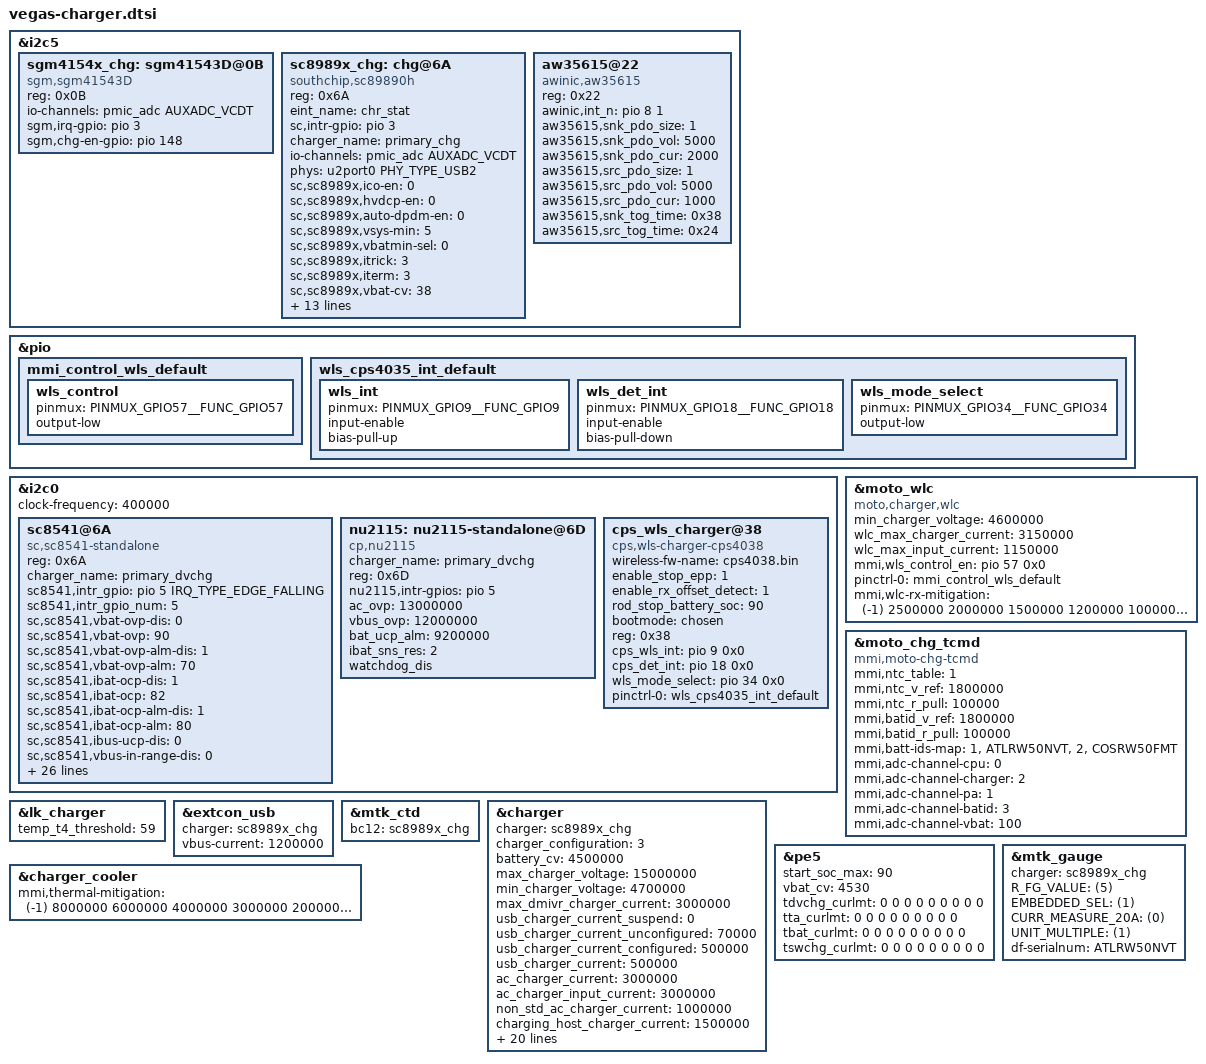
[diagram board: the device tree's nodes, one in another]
/*
 * Copyright (c) 2019 MediaTek Inc.
 *
 * This program is free software; you can redistribute it and/or modify
 * it under the terms of the GNU General Public License version 2 as
 * published by the Free Software Foundation.
 *
 * This program is distributed in the hope that it will be useful,
 * but WITHOUT ANY WARRANTY; without even the implied warranty of
 * MERCHANTABILITY or FITNESS FOR A PARTICULAR PURPOSE.  See the
 * GNU General Public License for more details.
 */
#include <dt-bindings/iio/mt635x-auxadc.h>
&i2c5 {
	sgm4154x_chg: sgm41543D@0B {
		status = "okay";
		compatible = "sgm,sgm41543D";
		reg = <0x0B>;
                io-channels = <&pmic_adc AUXADC_VCDT>;
		io-channel-names = "pmic_vbus";
		sgm,irq-gpio = <&pio 3 IRQ_TYPE_EDGE_FALLING>;     //irq num base on hardware design
		sgm,chg-en-gpio = <&pio 148 0>;   //gpio num base on hardware design  1.MTK parent node name is pio  2.QUALCOMM parent node name is tlmm or other
	};
	sc8989x_chg: chg@6A {
		compatible = "southchip,sc89890h";
		reg = <0x6A>;
		status = "okay";
		eint_name = "chr_stat";
		sc,intr-gpio = <&pio 3 IRQ_TYPE_EDGE_FALLING>;
		charger_name = "primary_chg";
		io-channels = <&pmic_adc AUXADC_VCDT>;
		io-channel-names = "pmic_vbus";
		phys = <&u2port0 PHY_TYPE_USB2>;
		phy-names = "usb2-phy";
		sc,sc8989x,ico-en = <0>;
		sc,sc8989x,hvdcp-en = <0>;
		sc,sc8989x,auto-dpdm-en = <0>;
		sc,sc8989x,vsys-min = <5>; /*3500mV*/
		sc,sc8989x,vbatmin-sel = <0>; /*0:2.9V 1:2.5V*/
		sc,sc8989x,itrick = <3>; /*60 + val *60*/
		sc,sc8989x,iterm = <3>; /*30 + val * 60*/
		sc,sc8989x,vbat-cv = <38>; /*3840 + val * 16*/
		sc,sc8989x,vbat-low = <1>; /*0:2.8V 1:3V*/
		sc,sc8989x,vrechg = <0>; /*0:100mV 1:200mV*/
		sc,sc8989x,en-term = <1>;
		sc,sc8989x,stat-dis = <0>;
		sc,sc8989x,wd-time = <0>; /*0:Dis 1:40s 2:80s 3:160s*/
		sc,sc8989x,en-timer = <1>;
		sc,sc8989x,charge-timer = <2>; /*0:5h 1:8h 2:12h 3:20h*/
		sc,sc8989x,bat-comp = <0>; /*val * 20*/
		sc,sc8989x,vclamp = <0>; /*val *32*/
		sc,sc8989x,votg = <12>; /*3900 + val * 100*/
		sc,sc8989x,iboost = <7>; /*0:0.5A 3:1.4A 5:1.875A 7:2.45A*/
		sc,sc8989x,force_vindpm = <0>;
		sc,sc8989x,vindpm = <18>; /*2600 + val * 100*/
	};
        aw35615@22 {
                compatible = "awinic,aw35615";
                reg = <0x22>;
                status = "okay";
                awinic,int_n = <&pio 8 1>;
                aw35615,snk_pdo_size = <1>; /* set sink pdo num*/
                aw35615,snk_pdo_vol = <5000>; /* set sink pdo voltage mV*/
                aw35615,snk_pdo_cur = <2000>; /* set sink pdo current mA*/
                aw35615,src_pdo_size = <1>; /* set source pdo num*/
                aw35615,src_pdo_vol = <5000>; /* set source pdo voltage mV*/
                aw35615,src_pdo_cur = <1000>; /* set source pdo current mA*/
                aw35615,snk_tog_time = <0x38>; /* set toggle sink time */
                aw35615,src_tog_time = <0x24>; /* set toggle source time */
        };
};

&pio {
       mmi_control_wls_default: mmi_control_wls_default {
               wls_control {
                       pinmux = <PINMUX_GPIO57__FUNC_GPIO57>;
                      output-low;
               };
       };

       wls_cps4035_int_default: wls_cps4035_int_default {
               wls_int {
                       pinmux = <PINMUX_GPIO9__FUNC_GPIO9>;
                       input-enable;
                       bias-pull-up;
               };
               wls_det_int {
                       pinmux = <PINMUX_GPIO18__FUNC_GPIO18>;
                       input-enable;
                       bias-pull-down;
               };
               wls_mode_select {
                       pinmux = <PINMUX_GPIO34__FUNC_GPIO34>;
                       output-low;
                 };
       };
};

&i2c0 {
	clock-frequency = <400000>;
	sc8541@6A {
		compatible = "sc,sc8541-standalone";
		reg = <0x6A>;
		charger_name = "primary_dvchg";
		sc8541,intr_gpio = <&pio 5 IRQ_TYPE_EDGE_FALLING>;
		sc8541,intr_gpio_num = <5>;
		sc,sc8541,vbat-ovp-dis = <0>;
		sc,sc8541,vbat-ovp = <90>; /*3840 + val * 10*/
		sc,sc8541,vbat-ovp-alm-dis = <1>;
		sc,sc8541,vbat-ovp-alm = <70>; /*3840 + val * 10*/
		sc,sc8541,ibat-ocp-dis = <1>;
		sc,sc8541,ibat-ocp  = <82>; /*val * 100*/
		sc,sc8541,ibat-ocp-alm-dis = <1>;
		sc,sc8541,ibat-ocp-alm = <80>; /*val * 100*/
		sc,sc8541,ibus-ucp-dis = <0>;
		sc,sc8541,vbus-in-range-dis = <0>;
		sc,sc8541,vbus-pd-en = <0>;
		sc,sc8541,vbus-ovp = <80>; /*7000 + val * 50*/
		sc,sc8541,vbus-ovp-alm-dis = <1>;
		sc,sc8541,vbus-ovp-alm = <34>; /*7000 + val * 50*/
		sc,sc8541,ibus-ocp-dis = <0>;
		sc,sc8541,ibus-ocp = <13>; /*1000 + val * 250*/
		sc,sc8541,tshut-dis = <1>;
		sc,sc8541,tsbus-flt-dis = <1>;
		sc,sc8541,tsbat-flt-dis = <1>;
		sc,sc8541,tdie-alm = <200>; /*25 + val * 0.5*/
		sc,sc8541,tsbus-flt = <21>;
		sc,sc8541,tsbat-flt = <21>;
		sc,sc8541,vac1-ovp = <2>; /*0:6.5V 1:10.5V 2:12V 3:14V 4:16V 5~7:18V*/
		sc,sc8541,vac2-ovp = <3>; /*0:6.5V 1:10.5V 2:12V 3:14V 4:16V 5~7:18V*/
		sc,sc8541,vac1-pd-en = <0>;
		sc,sc8541,vac2-pd-en = <0>;
		sc,sc8541,fsw-set = <5>; /*0:200KHz 1:300KHz 2:400KHz
					3:500KHz 4:600KHz 5:650KHz 6:700KHz 7:750KHz*/
		sc,sc8541,wd-timeout = <0>; /*0:0.5s 1:1s 2:5s 3:30s*/
		sc,sc8541,wd-timeout-dis = <1>;
		sc,sc8541,ibat-sns-r = <0>; /*0:2mho 1:5mho*/
		sc,sc8541,ss-timeout = <7>; /*0:6.25ms 1:12.5ms 2:25ms 3:50ms
					4:100ms 5:400ms 6:1.5s 7:10s*/
		sc,sc8541,ibus-ucp-fall-dg = <1>;
		sc,sc8541,vout-ovp-dis = <0>;
		sc,sc8541,vout-ovp = <3>; /*4700 + val * 100*/
		sc,sc8541,pmid2out-uvp = <7>; /*50 + val * 25*/
		sc,sc8541,pmid2out-ovp = <7>; /*150 + val * 50*/
	};

	nu2115: nu2115-standalone@6D {
		compatible = "cp,nu2115";
		status = "okay";
		charger_name = "primary_dvchg";
		reg = <0x6D>;
		nu2115,intr-gpios = <&pio 5 0x0>;
		ac_ovp = <13000000>;
		vbus_ovp = <12000000>;
		bat_ucp_alm = <9200000>;
		ibat_sns_res = <2>;
		watchdog_dis;
	};

	cps_wls_charger@38 {
               compatible = "cps,wls-charger-cps4038";
               wireless-fw-name = "cps4038.bin";
               enable_stop_epp = <1>;
               enable_rx_offset_detect = <1>;
               /*stop rx offset detect battery soc*/
               rod_stop_battery_soc = <90>;
               bootmode = <&chosen>;
               reg = <0x38>;
               cps_wls_int = <&pio 9 0x0>;
               cps_det_int = <&pio 18 0x0>;
               wls_mode_select = <&pio 34 0x0>;
               pinctrl-names = "default";
               pinctrl-0 = <&wls_cps4035_int_default>;
               status = "okay";
       };

};

&moto_wlc {
       compatible = "moto,charger,wlc";
       min_charger_voltage = <4600000>;
       wlc_max_charger_current = <3150000>;
       wlc_max_input_current = <1150000>;
       mmi,wls_control_en = <&pio 57 0x0>;
       pinctrl-names = "default";
       pinctrl-0 = <&mmi_control_wls_default>;
       #cooling-cells = <2>;
       mmi,wlc-rx-mitigation = <(-1) 2500000 2000000 1500000 1200000
                                                       1000000 800000 500000>;
};

&moto_chg_tcmd {
                compatible = "mmi,moto-chg-tcmd";
                status = "okay";

                mmi,ntc_table = <1>;
                mmi,ntc_v_ref = <1800000>;
                mmi,ntc_r_pull = <100000>;

                mmi,batid_v_ref = <1800000>;
                mmi,batid_r_pull = <100000>;
                mmi,batt-ids-map = "1", "ATLRW50NVT", "2", "COSRW50FMT";
                mmi,adc-channel-cpu = <0>;
                mmi,adc-channel-charger = <2>;
                mmi,adc-channel-pa = <1>;
                mmi,adc-channel-batid = <3>;
                mmi,adc-channel-vbat = <100>;
};

&lk_charger {
        temp_t4_threshold = <59>;
};

&extcon_usb {
	charger = <&sc8989x_chg>;
	vbus-current = <1200000>;
};

&mtk_ctd {
	bc12 = <&sc8989x_chg>;
};
&charger {
         charger = <&sc8989x_chg>;
         charger_configuration= <3>;
         /* common */
         battery_cv = <4500000>;
         max_charger_voltage = <15000000>;
         min_charger_voltage = <4700000>;
         max_dmivr_charger_current = <3000000>;

         //enable_pe_plus;
         //enable_sw_jeita;

         /* charging current */
         usb_charger_current_suspend = <0>;
         usb_charger_current_unconfigured = <70000>;
         usb_charger_current_configured = <500000>;
         usb_charger_current = <500000>;
         ac_charger_current = <3000000>;
         ac_charger_input_current = <3000000>;
         non_std_ac_charger_current = <1000000>;
         charging_host_charger_current = <1500000>;
         apple_1_0a_charger_current = <650000>;
         apple_2_1a_charger_current = <800000>;
         ta_ac_charger_current = <3600000>;
         typec_limit_aicr = <3000000>;

         /* PE */
         ta_ac_9v_input_current = <2000000>;
         ta_ac_7v_input_current = <2000000>;

         //mmi config
         mmi,iterm-ma = <487>;
         mmi,mmi-temp-zones =
			<0 4200 1000  0>,
			<10 4250 3000 1000>,
			<15 0 3000 3000>,
			<45 4300 6000 5200>,
			<45 4400 5200 4000>,
			<60 4200 4000 0>;

	mmi,mmi-ffc-zones = <0 4200 487>,
			<10 4500 487>,
			<15 4500 487>,
			<25 4530 523>,
			<35 4530 590>,
			<45 4530 871>,
			<60 4200 487>;

         mmi,enable-charging-limit;
         mmi,upper-limit-capacity = <65>;
         mmi,lower-limit-capacity = <60>;
         mmi,vfloat-comp-uv = <0>;
         mmi,enable-mux;
         fast_charging_indicator = <0x8010>;
};

&pe5 {
	start_soc_max = <90>;
	vbat_cv = <4530>;
	tdvchg_curlmt = <0 0 0 0 0 0 0 0 0>;
	tta_curlmt = <0 0 0 0 0 0 0 0 0>;
	tbat_curlmt = <0 0 0 0 0 0 0 0 0>;
	tswchg_curlmt = <0 0 0 0 0 0 0 0 0>;
};

&charger_cooler {
       mmi,thermal-mitigation = <(-1) 8000000 6000000 4000000 3000000
                               2000000 1000000 500000 300000>;
};

&mtk_gauge {
	charger = <&sc8989x_chg>;
	R_FG_VALUE = <(5)>; /*R_sense resistance*/
	EMBEDDED_SEL = <(1)>;
	CURR_MEASURE_20A = <(0)>;
	UNIT_MULTIPLE = <(1)>;
	df-serialnum = "ATLRW50NVT";
	#include "bat_setting/vegas_alt_battery_table_ext.dtsi"
	#include "bat_setting/vegas_cos_battery_table_ext.dtsi"
};
